# CY8C3246AXI_138 register map
File version: 0.1
CY8C32
Registers are 8-bit, read-write, no defined reset value unless marked. A register's access mark holds for its fields unless they carry their own. Offsets are from the block's base; lines under a group give offsets from that group; [hi:lo] are bit positions; {n}, {i} and the like mark numbered series; 'fields as' and 'values as' point back to an identical list; <NAME> marks a mode.

## Memory map
0x0000640A QuadDecoder size 0x65
0x0000640A QuadDecoder_Cnt8 size 0x94
0x00006428 UART size 0x45
0x0000646F SPIS size 0xFC
0x00006476 PWM size 0x121

## UART
Base 0x00006428
0x00 RX_UART_RX_ADDRESS1 — RX Address1 Register
0x10 RX_UART_RX_ADDRESS2 — RX Address2 Register
0x20 RX_UART_RX_DATA — RX Data Register
0x24 TX_UART_TX_DATA — TX Data Register
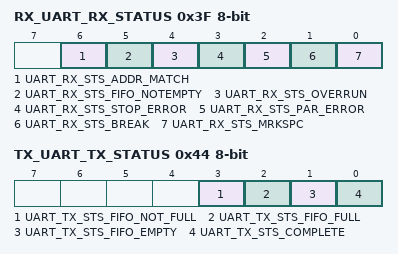
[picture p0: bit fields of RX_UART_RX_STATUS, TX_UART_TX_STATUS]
0x3F RX_UART_RX_STATUS — RX status register
  [6] UART_RX_STS_ADDR_MATCH ro, [5] UART_RX_STS_FIFO_NOTEMPTY ro, [4] UART_RX_STS_OVERRUN ro, [3] UART_RX_STS_STOP_ERROR ro, [2] UART_RX_STS_PAR_ERROR ro, [1] UART_RX_STS_BREAK ro, [0] UART_RX_STS_MRKSPC ro
0x44 TX_UART_TX_STATUS — TX status register
  [3] UART_TX_STS_FIFO_NOT_FULL ro, [2] UART_TX_STS_FIFO_FULL ro, [1] UART_TX_STS_FIFO_EMPTY ro, [0] UART_TX_STS_COMPLETE ro

## SPIS
Base 0x0000646F
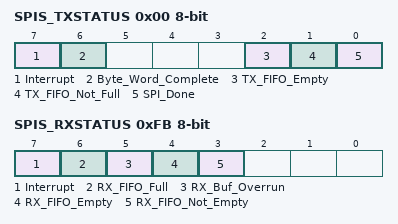
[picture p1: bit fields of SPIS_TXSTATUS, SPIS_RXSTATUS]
0x00 SPIS_TXSTATUS
  [7] Interrupt ro — Set when interrupt occurs
  [6] Byte_Word_Complete ro — Set when a byte/word transmit has completed
  [2] TX_FIFO_Empty ro — Set when the TX Data FIFO is empty
  [1] TX_FIFO_Not_Full ro — Set when the TX Data FIFO is not full
  [0] SPI_Done ro — Set when all of the data in the transmit FIFO has been sent. Set when Byte/Word Complete has been set and TX Data FIFO is empty
0x9B SPIS_TX_DATA 16-bit
0x9B SPIS_RX_DATA 16-bit
0xFB SPIS_RXSTATUS
  [7] Interrupt ro — Set when interrupt occurs
  [6] RX_FIFO_Full ro — Set when the RX Data FIFO is full
  [5] RX_Buf_Overrun ro — Set when RX Data has overrun the 4 byte/word FIFO without being moved to the RX buffer cmemory array (if one exists)
  [4] RX_FIFO_Empty ro — Set when the RX Data FIFO is empty
  [3] RX_FIFO_Not_Empty ro — Set when the RX Data FIFO is not empty. That is, at least one byte/word is in the RX FIFO

## PWM
Base 0x00006476
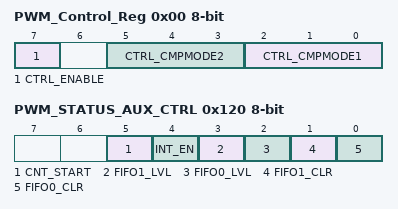
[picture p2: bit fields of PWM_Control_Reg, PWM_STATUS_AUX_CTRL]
0x00 PWM_Control_Reg — UDB Control Register - Assigned Control Register Value
  [7] CTRL_ENABLE — Enable the PWM
  [5:3] CTRL_CMPMODE2 — Compare mode 2
  [2:0] CTRL_CMPMODE1 — Compare mode 1
0xB0 PWM_COMPARE_Reg_ — UDB.D0 - Assigned Compare Value
0x120 PWM_STATUS_AUX_CTRL — UDB Auxilliary Control Register
  [5] CNT_START — FIFO0 clear
    0=E_CNT_START0 (Disable counter); 1=E_CNT_START1 (Enable counter)
  [4] INT_EN
    0=E_INT_EN0 (Interrupt disabled); 1=E_INT_EN1 (Interrupt enabled)
  [3] FIFO1_LVL — FIFO level
    0=E_FIFO_LVL_0 (FIFO LVL: input mode: FIFO not full; output mode: FIFO not empty); 1=E_FIFO_LVL_1 (FIFO LVL: input mode: FIFO at least 1/2 empty; output mode: FIFO at least 1/2 full)
  [2] FIFO0_LVL — FIFO level
    values as FIFO1_LVL
  [1] FIFO1_CLR — FIFO1 clear
    0=E_FIFO_CLR_0 (Normal FIFO operation); 1=E_FIFO_CLR_1 (Clear FIFO state)
  [0] FIFO0_CLR — FIFO0 clear
    values as FIFO1_CLR

## QuadDecoder
Base 0x0000640A
0x00 QuadDecoder_Cnt8_COUNTER — Counter value
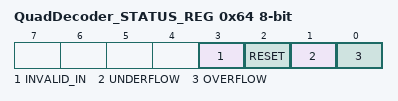
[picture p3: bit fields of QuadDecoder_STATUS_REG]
0x64 QuadDecoder_STATUS_REG — Quadrature Decoder Status Register
  [3] INVALID_IN ro — Invalid state transition on the A and B inputs
  [2] RESET ro — Counter Reset due index
  [1] UNDERFLOW ro — Counter underflow
  [0] OVERFLOW ro — Counter overflow

## QuadDecoder_Cnt8
Base 0x0000640A
0x00 QuadDecoder_Cnt8_COUNTER — UDB.A0 - Current Counter Value
0x20 QuadDecoder_Cnt8_PERIOD — UDB.D0 - Assigned Period
0x30 QuadDecoder_Cnt8_COMPARE — UDB.D1 - Assigned Compare Value
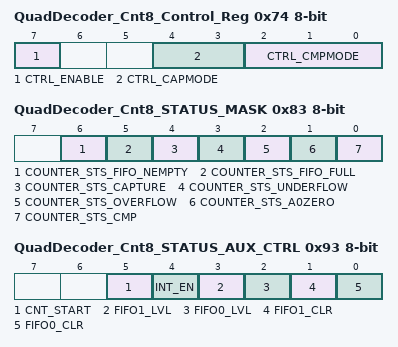
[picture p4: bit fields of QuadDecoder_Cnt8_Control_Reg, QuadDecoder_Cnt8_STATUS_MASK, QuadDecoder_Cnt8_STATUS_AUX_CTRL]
0x74 QuadDecoder_Cnt8_Control_Reg — UDB Control Register - Assigned Control Register Value
  [7] CTRL_ENABLE — Enable Counter
  [4:3] CTRL_CAPMODE — Capture mode
  [2:0] CTRL_CMPMODE — Compare mode
0x83 QuadDecoder_Cnt8_STATUS_MASK — UDB Status bits Interrupt Mask Enable Register
  [6] COUNTER_STS_FIFO_NEMPTY — FIFO Not Empty Status
  [5] COUNTER_STS_FIFO_FULL — FIFO Full Status
  [4] COUNTER_STS_CAPTURE — Capture Status
  [3] COUNTER_STS_UNDERFLOW — Underflow status
  [2] COUNTER_STS_OVERFLOW — Overflow status
  [1] COUNTER_STS_A0ZERO — A0 Zero ouput status
  [0] COUNTER_STS_CMP — Compare output status
0x93 QuadDecoder_Cnt8_STATUS_AUX_CTRL — UDB Auxilliary Control Register
  fields as PWM.PWM_STATUS_AUX_CTRL
